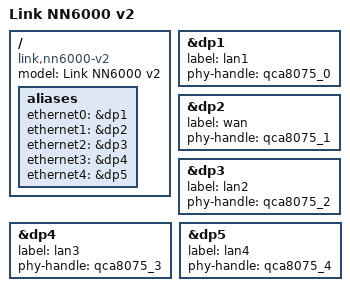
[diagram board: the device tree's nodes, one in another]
// SPDX-License-Identifier: GPL-2.0-or-later OR MIT

/dts-v1/;

#include "ipq6000-link.dtsi"

/ {
	model = "Link NN6000 v2";
	compatible = "link,nn6000-v2", "qcom,ipq6018";

	aliases {
		ethernet0 = &dp1;
		ethernet1 = &dp2;
		ethernet2 = &dp3;
		ethernet3 = &dp4;
		ethernet4 = &dp5;
	};
};

&dp1 {
	label = "lan1";
	phy-handle = <&qca8075_0>;
	status = "okay";
};

&dp2 {
	label = "wan";
	phy-handle = <&qca8075_1>;
	status = "okay";
};

&dp3 {
	label = "lan2";
	phy-handle = <&qca8075_2>;
	status = "okay";
};

&dp4 {
	label = "lan3";
	phy-handle = <&qca8075_3>;
	status = "okay";
};

&dp5 {
	label = "lan4";
	phy-handle = <&qca8075_4>;
	status = "okay";
};
